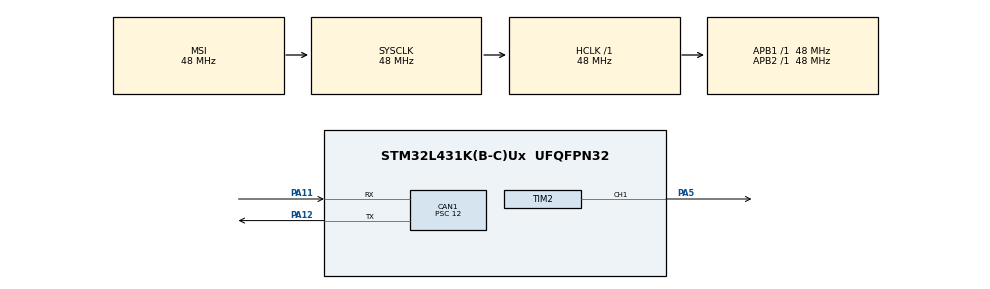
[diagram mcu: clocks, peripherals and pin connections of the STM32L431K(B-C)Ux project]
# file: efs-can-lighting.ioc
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CAN1.BS1=CAN_BS1_2TQ
CAN1.BS2=CAN_BS2_1TQ
CAN1.CalculateBaudRate=1000000
CAN1.CalculateTimeBit=1000
CAN1.CalculateTimeQuantum=250.0
CAN1.Mode=CAN_MODE_NORMAL
CAN1.Prescaler=12
Dma.Request0=TIM2_CH1
Dma.TIM2_CH1.0.Direction=DMA_MEMORY_TO_PERIPH
Dma.TIM2_CH1.0.Instance=DMA1_Channel5
Dma.TIM2_CH1.0.MemDataAlignment=DMA_MDATAALIGN_BYTE
Dma.TIM2_CH1.0.MemInc=DMA_MINC_ENABLE
Dma.TIM2_CH1.0.Mode=DMA_CIRCULAR
Dma.TIM2_CH1.0.PeriphDataAlignment=DMA_PDATAALIGN_WORD
Dma.TIM2_CH1.0.PeriphInc=DMA_PINC_DISABLE
Dma.TIM2_CH1.0.Priority=DMA_PRIORITY_HIGH
Mcu.Family=STM32L4
Mcu.Name=STM32L431K(B-C)Ux
Mcu.Package=UFQFPN32
NVIC.CAN1_RX0_IRQn=true\:0\:0\:false\:false\:true\:true\:true\:true
NVIC.DMA1_Channel5_IRQn=true\:0\:0\:false\:false\:true\:false\:true\:true
NVIC.PriorityGroup=NVIC_PRIORITYGROUP_4
PA0.Mode=HSE-External-Clock-Source-for-LittleOrca
PA0.Signal=RCC_CK_IN
PA11.GPIO_PuPd=GPIO_NOPULL
PA11.Mode=CAN_Activate
PA11.Signal=CAN1_RX
PA12.Mode=CAN_Activate
PA12.Signal=CAN1_TX
PA13\ (JTMS-SWDIO).Mode=Trace_Asynchronous_SW
PA13\ (JTMS-SWDIO).Signal=SYS_JTMS-SWDIO
PA14\ (JTCK-SWCLK).Mode=Trace_Asynchronous_SW
PA14\ (JTCK-SWCLK).Signal=SYS_JTCK-SWCLK
PA5.Signal=S_TIM2_CH1
PB3\ (JTDO-TRACESWO).Mode=Trace_Asynchronous_SW
PB3\ (JTDO-TRACESWO).Signal=SYS_JTDO-SWO
ProjectManager.HeapSize=0x200
ProjectManager.StackSize=0x400
ProjectManager.TargetToolchain=STM32CubeIDE
RCC.ADCFreq_Value=192000000
RCC.AHBFreq_Value=48000000
RCC.APB1Freq_Value=48000000
RCC.APB1TimFreq_Value=48000000
RCC.APB2Freq_Value=48000000
RCC.APB2TimFreq_Value=48000000
RCC.CortexFreq_Value=48000000
RCC.HCLKFreq_Value=48000000
RCC.HSE_VALUE=8000000
RCC.HSI48_VALUE=48000000
RCC.HSI_VALUE=16000000
RCC.LSE_VALUE=32768
RCC.MSIClockRange=RCC_MSIRANGE_11
RCC.MSI_VALUE=48000000
RCC.SYSCLKFreq_VALUE=48000000
RCC.VCOOutputFreq_Value=384000000
SH.S_TIM2_CH1.0=TIM2_CH1,PWM Generation1 CH1
TIM2.Channel-PWM\ Generation1\ CH1=TIM_CHANNEL_1
TIM2.Period=96
VP_TIM2_VS_ClockSourceINT.Mode=Internal
board=custom

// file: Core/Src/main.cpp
#include "main.h"
#include "can.h"
#include "dma.h"
#include "tim.h"
#include "can_manager.hpp"
#include "new_lighting_controller.hpp"

void SystemClock_Config(void);

int main(void)
{

	/* MCU Configuration--------------------------------------------------------*/

	/* Reset of all peripherals, Initializes the Flash interface and the Systick. */
	HAL_Init();

	/* Configure the system clock */
	SystemClock_Config();

	/* Initialize all configured peripherals */
	MX_DMA_Init();
	MX_CAN1_Init();
	MX_TIM2_Init();

	/* USER CODE BEGIN 2 */

	if (initCAN() != PINECAN_OK)
	{
		Error_Handler();
	}

	// initialise the LED PWM/DMA output and set GND as default
	led_init();

	/* Infinite loop */
	/* USER CODE BEGIN WHILE */

	uint64_t raw_vehicle_state = 0;
	bool new_data = false;
	bool stay_in_loop = true;
	uint8_t flight_state = 0;

	while (1)
	{
		/* USER CODE END WHILE */

		/* USER CODE BEGIN 3 */

		while (stay_in_loop)
		{

			static uint32_t lastLedTick = 0;
			static uint32_t tick = 0;
			if (HAL_GetTick() - lastLedTick >= 20)
			{
				lastLedTick = HAL_GetTick();
				Generate_Leds(tick); // advance animations, expand active zones into colour_buffer
				Push_Leds();		 // bit-encode colour_buffer into the DMA-streamed bank buffer
				tick++;
			}

			// Service PineCAN housekeeping (1ms tick-gated pinecan1ms call)
			CANManager::service();

			// Re-read the cache each inner iteration so new CAN data is visible
			raw_vehicle_state = CANManager::getLatestVehicleState();

			// Step 2: check if data changed since last call
			new_data = CANManager::vehicleStateChanged(raw_vehicle_state);

			if (new_data)
			{
				stay_in_loop = false;
			}
		}

		// read cache and decode — gives us the current flight state
		flight_state = interpretVehicleState(raw_vehicle_state);

		Select_Pattern(flight_state);

		new_data = false;
		stay_in_loop = true;
	}
	/* USER CODE END 3 */
}

void SystemClock_Config(void)
{
	RCC_OscInitTypeDef RCC_OscInitStruct = {0};
	RCC_ClkInitTypeDef RCC_ClkInitStruct = {0};

	/** Configure the main internal regulator output voltage
	 */
	if (HAL_PWREx_ControlVoltageScaling(PWR_REGULATOR_VOLTAGE_SCALE1) != HAL_OK)
	{
		Error_Handler();
	}

	/** Initializes the RCC Oscillators according to the specified parameters
	 * in the RCC_OscInitTypeDef structure.
	 */
	RCC_OscInitStruct.OscillatorType = RCC_OSCILLATORTYPE_MSI;
	RCC_OscInitStruct.MSIState = RCC_MSI_ON;
	RCC_OscInitStruct.MSICalibrationValue = 0;
	RCC_OscInitStruct.MSIClockRange = RCC_MSIRANGE_11;
	RCC_OscInitStruct.PLL.PLLState = RCC_PLL_NONE;
	if (HAL_RCC_OscConfig(&RCC_OscInitStruct) != HAL_OK)
	{
		Error_Handler();
	}

	/** Initializes the CPU, AHB and APB buses clocks
	 */
	RCC_ClkInitStruct.ClockType = RCC_CLOCKTYPE_HCLK | RCC_CLOCKTYPE_SYSCLK | RCC_CLOCKTYPE_PCLK1 | RCC_CLOCKTYPE_PCLK2;
	RCC_ClkInitStruct.SYSCLKSource = RCC_SYSCLKSOURCE_MSI;
	RCC_ClkInitStruct.AHBCLKDivider = RCC_SYSCLK_DIV1;
	RCC_ClkInitStruct.APB1CLKDivider = RCC_HCLK_DIV1;
	RCC_ClkInitStruct.APB2CLKDivider = RCC_HCLK_DIV1;

	if (HAL_RCC_ClockConfig(&RCC_ClkInitStruct, FLASH_LATENCY_2) != HAL_OK)
	{
		Error_Handler();
	}
}

void Error_Handler(void)
{
	__disable_irq();
	while (1)
	{
	}
}
